# STM32H7B0 register map
File version: 1.7
CPU: CM7 r0p1, little endian, MPU, FPU, 4 interrupt priority bits
Registers are 32-bit, read-write, reset 0x0 unless marked. A register's access mark holds for its fields unless they carry their own. Offsets are from the block's base; [hi:lo] are bit positions; {n}, {i} and the like mark numbered series; 'fields as' and 'values as' point back to an identical list.

## OTFDEC1 — On-The-Fly Decryption engine
Base 0x5200B800
Same registers: OTFDEC2 0x5200BC00
0x00 CR — OTFDEC control register
  [0] ENC — Encryption mode bit
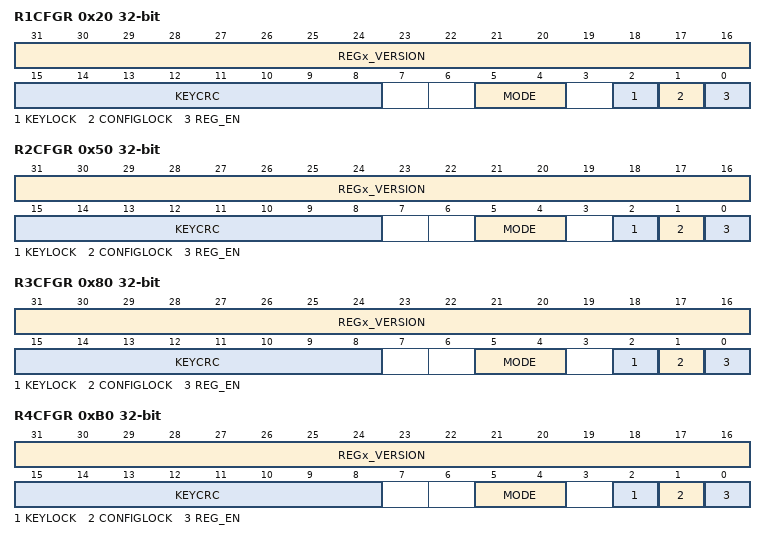
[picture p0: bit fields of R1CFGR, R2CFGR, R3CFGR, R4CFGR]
0x20 R1CFGR access per field — OTFDEC region x configuration register
  [31:16] REGx_VERSION rw — region firmware version
  [15:8] KEYCRC ro — region key 8-bit CRC
  [5:4] MODE rw — operating mode
  [2] KEYLOCK rw — region key lock
  [1] CONFIGLOCK rw — region config lock
  [0] REG_EN rw — region on-the-fly decryption enable
0x24 R1STARTADDR — OTFDEC region x start address register
  [31:0] REGx_START_ADDR — Region AXI start address
0x28 R1ENDADDR reset 0xFFF — OTFDEC region x end address register
  [31:0] REGx_END_ADDR — Region AXI end address
0x2C R1NONCER0 — OTFDEC region x nonce register 0
  [31:0] REGx_NONCE
0x30 R1NONCER1 — OTFDEC region x nonce register 1
  [31:0] REGx_NONCE — Region nonce
{0x4+0x30*i} R{i}KEYR0 wo (i=1..4) — OTFDEC region x key register 0
  [31:0] REGx_KEY
{0x8+0x30*i} R{i}KEYR1 wo (i=1..4) — OTFDEC region x key register 1
  [31:0] REGx_KEY
0x3C R1KEYR2 wo — OTFDEC region x key register 2
  [31:0] REGx_KEY
{0x10+0x30*i} R{i}KEYR3 wo (i=1..4) — OTFDEC region x key register 3
  [31:0] REGx_KEY
0x50 R2CFGR access per field — OTFDEC region x configuration register
  fields as R1CFGR
0x54 R2STARTADDR — OTFDEC region x start address register
  [31:0] REGx_START_ADDR — Region AXI start address
0x58 R2ENDADDR reset 0xFFF — OTFDEC region x end address register
  [31:0] REGx_END_ADDR — Region AXI end address
0x5C R2NONCER0 — OTFDEC region x nonce register 0
  [31:0] REGx_NONCE
0x60 R2NONCER1 — OTFDEC region x nonce register 1
  [31:0] REGx_NONCE — Region nonce, bits [63:32]REGx_NONCE[63:32]
0x6C R2KEYR2 wo — OTFDEC region x key register 2
  [31:0] REGx_KEY_
0x80 R3CFGR access per field — OTFDEC region x configuration register
  fields as R1CFGR
0x84 R3STARTADDR — OTFDEC region x start address register
  [31:0] REGx_START_ADDR — Region AXI start address
0x88 R3ENDADDR reset 0xFFF — OTFDEC region x end address register
  [31:0] REGx_END_ADDR — Region AXI end address
0x8C R4ENDADDR reset 0xFFF — OTFDEC region x end address register
  [31:0] REGx_END_ADDR — Region AXI end address
0x8C R3NONCER0 (alternate view of R4ENDADDR) — OTFDEC region x nonce register 0
  [31:0] REGx_NONCE
0x90 R3NONCER1 — OTFDEC region x nonce register 1
  [31:0] REGx_NONCE
0x9C R3KEYR2 wo — OTFDEC region x key register 2
  [31:0] REGx_KEY
0xB0 R4CFGR access per field — OTFDEC region x configuration register
  fields as R1CFGR
0xB4 R4STARTADDR — OTFDEC region x start address register
  [31:0] REGx_START_ADDR — Region AXI start address
0xBC R4NONCER0 — OTFDEC region x nonce register 0
  [31:0] REGx_NONCE
0xC0 R4NONCER1 — OTFDEC region x nonce register 1
  [31:0] REGx_NONCE
0xCC R4KEYR2 wo — OTFDEC region x key register 2
  [31:0] REGx_KEY
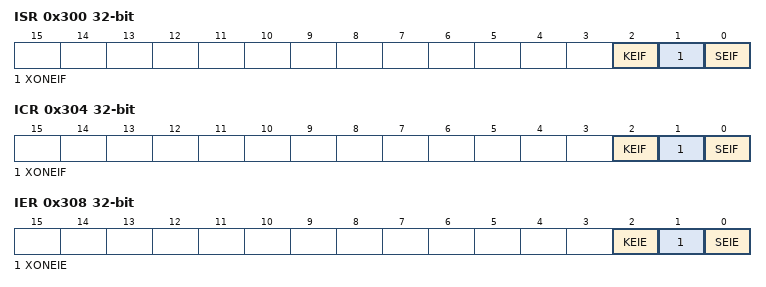
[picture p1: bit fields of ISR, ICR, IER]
0x300 ISR ro — OTFDEC interrupt status register
  [2] KEIF — Key Error Interrupt Flag status
  [1] XONEIF — Execute-only execute-Never Error Interrupt Flag status
  [0] SEIF — Security Error Interrupt Flag status
0x304 ICR ro — OTFDEC interrupt clear register
  [2] KEIF
  [1] XONEIF — Execute-only execute-Never Error Interrupt Flag clear
  [0] SEIF
0x308 IER — OTFDEC interrupt enable register
  [2] KEIE
  [1] XONEIE
  [0] SEIE — Security Error Interrupt Enable

## DBGMCU — Microcontroller Debug Unit
Base 0x5C001000
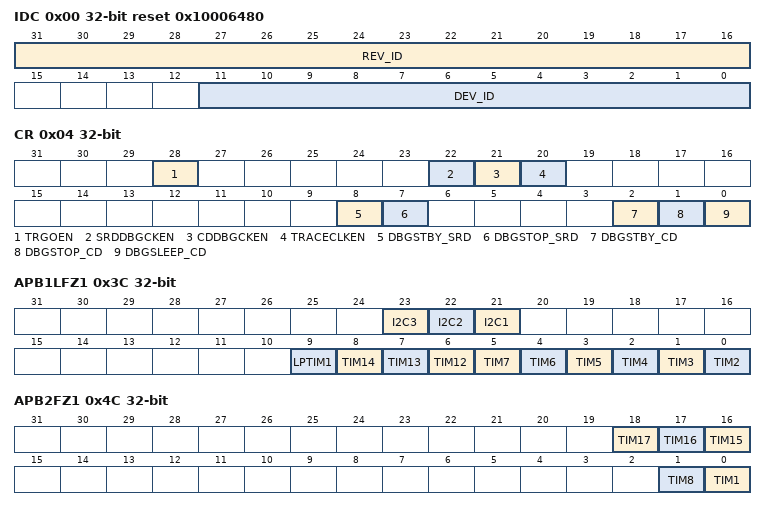
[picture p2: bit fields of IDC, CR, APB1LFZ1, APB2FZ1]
0x00 IDC ro reset 0x10006480 — DBGMCU Identity Code Register
  [31:16] REV_ID — Revision
  [11:0] DEV_ID — Device ID
0x04 CR — DBGMCU Configuration Register
  [28] TRGOEN — External trigger output enable
  [22] SRDDBGCKEN — SmartRun domain debug clock enable
  [21] CDDBGCKEN — CPU domain debug clock enable
  [20] TRACECLKEN — Trace port clock enable
  [8] DBGSTBY_SRD — debug in SmartRun domain Standby mode
  [7] DBGSTOP_SRD — debug in SmartRun domain Stop mode
  [2] DBGSTBY_CD — Allow D1 domain debug in Standby mode
  [1] DBGSTOP_CD — Allow D1 domain debug in Stop mode
  [0] DBGSLEEP_CD — Allow D1 domain debug in Sleep mode
0x34 APB3FZ1 — DBGMCU APB3 peripheral freeze register
  [6] WWDG — WWDG stop in debug
0x3C APB1LFZ1 — DBGMCU APB1L peripheral freeze register
  [23] I2C3 — I2C3 SMBUS timeout stop in debug
  [22] I2C2 — I2C2 SMBUS timeout stop in debug
  [21] I2C1 — I2C1 SMBUS timeout stop in debug
  [9] LPTIM1 — LPTIM1 stop in debug
  [8] TIM14 — TIM14 stop in debug
  [7] TIM13 — TIM13 stop in debug
  [6] TIM12 — TIM12 stop in debug
  [n-2] TIM{n} (n=2..7) — TIM{n} stop in debug
0x4C APB2FZ1 — DBGMCU APB2 peripheral freeze register
  [18] TIM17 — TIM17 stop in debug
  [17] TIM16 — TIM16 stop in debug
  [16] TIM15 — TIM15 stop in debug
  [1] TIM8 — TIM8 stop in debug
  [0] TIM1 — TIM1 stop in debug
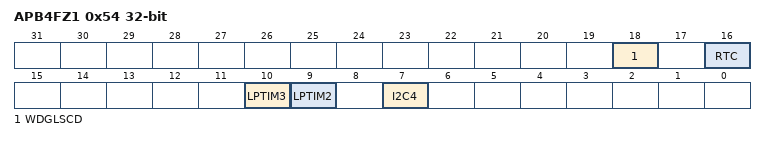
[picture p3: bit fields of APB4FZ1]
0x54 APB4FZ1 — DBGMCU APB4 peripheral freeze register
  [18] WDGLSCD — LS watchdog for CPU domain stop in debug
  [16] RTC — RTC stop in debug
  [10] LPTIM3 — LPTIM3 stop in debug
  [9] LPTIM2 — LPTIM2 stop in debug
  [7] I2C4 — I2C4 SMBUS timeout stop in debug
